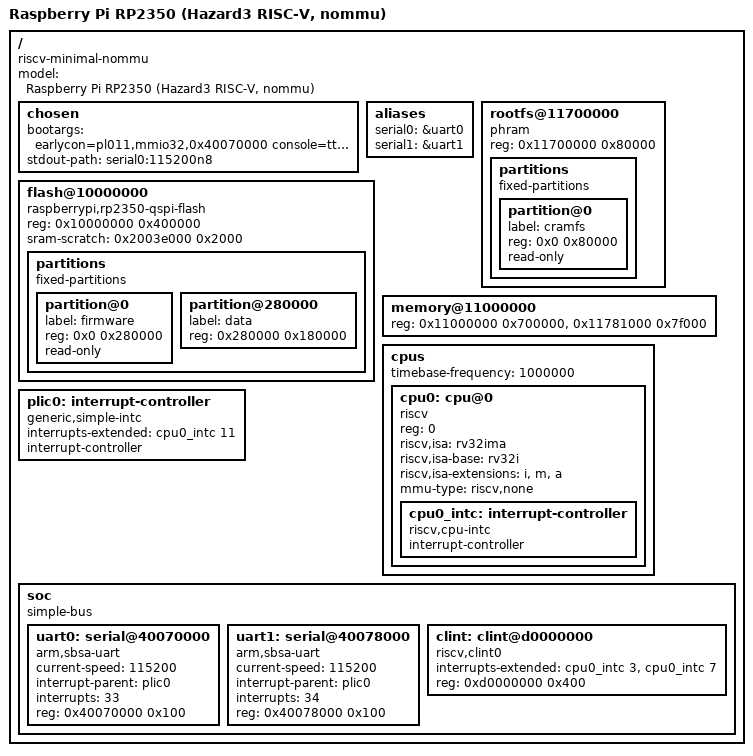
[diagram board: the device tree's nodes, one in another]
/dts-v1/;

/ {
	#address-cells = <1>;
	#size-cells = <1>;
	compatible = "riscv-minimal-nommu";
	model = "Raspberry Pi RP2350 (Hazard3 RISC-V, nommu)";

	chosen {
		bootargs = "earlycon=pl011,mmio32,0x40070000 console=ttyAMA0 root=mtd:cramfs rootfstype=cramfs ro";
		stdout-path = "serial0:115200n8";
	};

	aliases {
		serial0 = &uart0;
		serial1 = &uart1;
	};

	/*
	 * Reading the QSPI window while executing from PSRAM makes the shared
	 * QSPI bus switch chip selects constantly, so the bootloader copies the
	 * rootfs into PSRAM and the kernel never touches flash again.
	 *
	 * The 0x80000 size is duplicated in genimage.cfg (partition cramfs) and
	 * in the bootloader's ROOTFS_MAX_SIZE; post-image.sh checks that the
	 * built image still fits.  Change all three together.
	 */
	rootfs@11700000 {
		compatible = "phram";
		reg = <0x11700000 0x80000>;	/* 512KB cramfs copied from flash +2MB */

		partitions {
			#address-cells = <1>;
			#size-cells = <1>;
			compatible = "fixed-partitions";

			partition@0 {
				label = "cramfs";
				reg = <0x0 0x80000>;
				read-only;
			};
		};
	};

	/*
	 * The NOR flash on QMI chip select 0.  reg is its XIP address range,
	 * used only to derive the size: the driver never reads through that
	 * window, because enabling QMI direct mode turns every memory-mapped
	 * access into a bus error and the kernel runs from PSRAM on CS1.  All
	 * flash traffic is bit-banged from the SRAM scratch region below.
	 *
	 * sram-scratch is 8 KiB at the top of the bootloader's 256 KiB SRAM
	 * region.  The bootloader itself only reaches 0x20002ce0 and is dead
	 * once it jumps here, and the kernel has no SRAM support at all, so
	 * nothing else claims it.
	 */
	flash@10000000 {
		compatible = "raspberrypi,rp2350-qspi-flash";
		reg = <0x10000000 0x400000>;	/* 4 MiB on CS0 */
		sram-scratch = <0x2003e000 0x2000>;

		partitions {
			#address-cells = <1>;
			#size-cells = <1>;
			compatible = "fixed-partitions";

			/* Bootloader + DTB + kernel (all below 2M, bounded by
			 * post-image.sh) + the 512K cramfs at 2M.  Read-only so
			 * Linux cannot overwrite the image it booted from;
			 * upgrading still means picotool from the host. */
			partition@0 {
				label = "firmware";
				reg = <0x0 0x280000>;
				read-only;
			};
			partition@280000 {
				label = "data";
				reg = <0x280000 0x180000>;	/* 1.5 MiB */
			};
		};
	};

	memory@11000000 {
		device_type = "memory";
		/*
		 * 7MB below the rootfs, plus the 508KB of PSRAM above the DTB
		 * slot that used to be left unused.  The second range starts
		 * 4KB past 0x11780000 so it can never overlap the bootloader's
		 * DTB copy, whatever size the DTB grows to.
		 */
		reg = <0x11000000 0x700000>, <0x11781000 0x7f000>;
	};

	cpus {
		#address-cells = <1>;
		#size-cells = <0>;
		/* sys timer is in Hz */
		timebase-frequency = <1000000>;

		cpu0: cpu@0 {
			reg = <0>;
			device_type = "cpu";
			compatible = "riscv";
			/*
			 * Under-describes the silicon on purpose.  Hazard3 is
			 * rv32imac_zicsr_zifencei and the kernel is built with
			 * CONFIG_RISCV_ISA_C=y, but "c" stays out of this list:
			 * isa-extensions is authoritative (it and isa-base are
			 * both present, so RISCV_ISA_FALLBACK never applies),
			 * and "c" is a superset that would also enable zca/zcf/
			 * zcd.  Their only readers are that superset table and
			 * KVM, which is disabled, so omitting "c" costs hwcap
			 * and /proc/cpuisa reporting but no codegen.
			 *
			 * "a" is only truthful for on-chip SRAM: AMOs aimed at
			 * the PSRAM/XIP window fault, hence the rewrite patches.
			 */
			riscv,isa = "rv32ima";
			riscv,isa-base = "rv32i";
			riscv,isa-extensions = "i", "m", "a";
			mmu-type = "riscv,none";
			status = "okay";

			cpu0_intc: interrupt-controller {
				#interrupt-cells = <1>;
				#address-cells = <1>;
				interrupt-controller;
				compatible = "riscv,cpu-intc";
			};
		};
	};

	/*
	 * Not a PLIC: the RP2350 wires peripheral interrupts straight to the
	 * hart, handled by irq-simple-intc.c through CSRs.  The driver never
	 * maps registers, so there is no reg (the previous <0x0 0x0> was a
	 * bogus zero-length range at physical address 0).  It lives outside
	 * soc because a reg-less child of a simple-bus makes dtc warn, and
	 * this is hart-local state rather than an SoC MMIO device.
	 */
	plic0: interrupt-controller {
		interrupts-extended = <&cpu0_intc 11>;
		interrupt-controller;
		compatible = "generic,simple-intc";
		#address-cells = <0x00>;
		#interrupt-cells = <0x01>;
	};

	soc {
		#address-cells = <1>;
		#size-cells = <1>;
		compatible = "simple-bus";
		ranges;

		uart0: serial@40070000 {
			compatible = "arm,sbsa-uart";
			current-speed = <115200>;
			interrupt-parent = <&plic0>;
			interrupts = <33>;
			reg = <0x40070000 0x100>;
			status = "okay";
		};

		uart1: serial@40078000 {
			compatible = "arm,sbsa-uart";
			current-speed = <115200>;
			interrupt-parent = <&plic0>;
			interrupts = <34>;
			reg = <0x40078000 0x100>;
			status = "okay";
		};

		clint: clint@d0000000 {
			interrupts-extended = <&cpu0_intc 3>,
					      <&cpu0_intc 7>;
			reg = <0xd0000000 0x400>;
			compatible = "riscv,clint0";
		};
	};
};
